# FSS_FSAS_OTFA_REGS_53802000h register map
Vendor: Texas Instruments
Peripheral module from a debugger description file (folder AM261x).
Registers are 32-bit, read-write, reset 0x0 unless marked. A register's access mark holds for its fields unless they carry their own. Offsets are as the file gives them; lines under a group give offsets from that group; [hi:lo] are bit positions; {n}, {i} and the like mark numbered series; 'fields as' and 'values as' point back to an identical list; <NAME> marks a mode.

## FSAS_OTFA_REGS
0x00 FSAS_OTFA_REGS_REVID ro reset 0x47500101 — This register defines the revision and functional ID.
0x04 FSAS_OTFA_REGS_SCFG reset 0x2 — This register defines the power IDLE mode.
  [1:0] IDLE_MODE — IDLE MODE. 0x0: Force-idle mode: local target's idle state follows (acknowledges) the system's idle requests unconditionally, i.e. regardless of the IP module's internal requirements. Backup mode, for debug only. 0x1: No-idle mode: local target never enters idle state. Backup mode, for debug only. 0x2: Smart-idle mode: local target's idle state eventually follows (acknowledges) the system's idle requests, depending on the IP module's internal requirements. IP module shall not generate (IRQ- or DMA-request-related) wakeup events. 0x3: Reserved
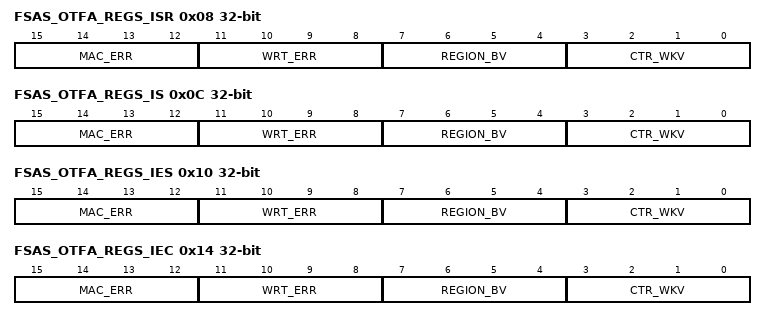
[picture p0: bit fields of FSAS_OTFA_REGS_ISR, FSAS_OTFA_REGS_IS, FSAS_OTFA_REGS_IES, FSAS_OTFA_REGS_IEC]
0x08 FSAS_OTFA_REGS_ISR — Per-event raw interrupt status vector Raw status is set even if event is not enabled. Write 1 to set the (raw) status, mostly for debug and SW testing.
  [15:12] MAC_ERR — Region MAC compare error event, Read MAC did not match the Write MAC. Write0:No action Read0:No event pending Read1:Event pending Write1:Set event (debug)
  [11:8] WRT_ERR — Region write error event, write cmd issues when write is disabled Write0:No action Read0:No event pending Read1:Event pending Write1:Set event (debug)
  [7:4] REGION_BV — Region overflow boundary event caused by a burst transaction crossed a start or end of a region. Write0:No action Read0:No event pending Read1:Event pending Write1:Set event (debug)
  [3:0] CTR_WKV — AES CTR enabled region violated Wrt Once Per Wrt Key rule. Write0:No action Read0:No event pending Read1:Event pending Write1:Set event (debug)
0x0C FSAS_OTFA_REGS_IS — Per-event 'enabled' interrupt status vector. Enabled status isn't set unless event is enabled. Write 1 to clear the status after interrupt has been serviced (raw status gets cleared, i.e. even if not enabled).
  [15:12] MAC_ERR — Region MAC compare error event, Read MAC did not match the Write MAC. Write0:No action Read0:No (enabled) event pending Read1:Event pending Write1:Clear event
  [11:8] WRT_ERR — Region write error event, write cmd issues when write is disabled. Write0:No action Read0:No (enabled) event pending Read1:Event pending Write1:Clear event
  [7:4] REGION_BV — Region overflow boundary event caused by a burst transaction crossing a start or end of a region. Write0:No action Read0:No (enabled) event pending Read1:Event pending Write1:Clear event Note: a RMW transaction can make create 2 events , 1st do to the orginal over lap and then 2nd do to the new wrt cmd. Also, a RM and RMW can create event on the 2nd transaction do to the over lap do to the expansion of the transaction.
  [3:0] CTR_WKV — AES CTR enabled region violated Wrt Once Per Wrt Key rule. Write0:No action Read0:No (enabled) event pending Read1:Event pending Write1:Clear event and reset counter
0x10 FSAS_OTFA_REGS_IES — Per-event interrupt enable bit vector. Write 1 to set (enable interrupt). Readout equal to corresponding _CLR register.
  [15:12] MAC_ERR — Region MAC compare error event, Read MAC did not match the Write MAC. Write0:No action Read0:Interrupt disabled (masked) Read1:Interrupt enabled Write1:Enable interrupt
  [11:8] WRT_ERR — Region write error event, write cmd issues when write is disabled. Write0:No action Read0:Interrupt disabled (masked) Read1:Interrupt enabled Write1:Enable interrupt
  [7:4] REGION_BV — Region overflow boundary event caused by a burst transaction crossing a start or end of a region. Write0:No action Read0:Interrupt disabled (masked) Read1:Interrupt enabled Write1:Enable interrupt
  [3:0] CTR_WKV — AES CTR enabled region violated Wrt Once Per Wrt Key rule. Write0:No action Read0:Interrupt disabled (masked) Read1:Interrupt enabled Write1:Enable interrupt
0x14 FSAS_OTFA_REGS_IEC — Per-event interrupt enable bit vector. Write 1 to clear (disable interrupt). Readout equal to corresponding _SET register.
  [15:12] MAC_ERR — Region MAC compare error event, Read MAC did not match the Write MAC. Write0:No action Read0:Interrupt disabled (masked) Read1:Interrupt enabled Write1:Enable interrupt
  [11:8] WRT_ERR — Region write error event, write cmd issues when write is disabled Write0:No action Read0:Interrupt disabled (masked) Read1:Interrupt enabled Write1:Disable interrupt
  [7:4] REGION_BV — Region overflow boundary event caused by a burst transaction crossing a start or end of a region. Write0:No action Read0:Interrupt disabled (masked) Read1:Interrupt enabled Write1:Disable interrupt
  [3:0] CTR_WKV — AES CTR enabled region violated Wrt Once Per Wrt Key rule. Write0:No action Read0:Interrupt disabled (masked) Read1:Interrupt enabled Write1:Disable interrupt
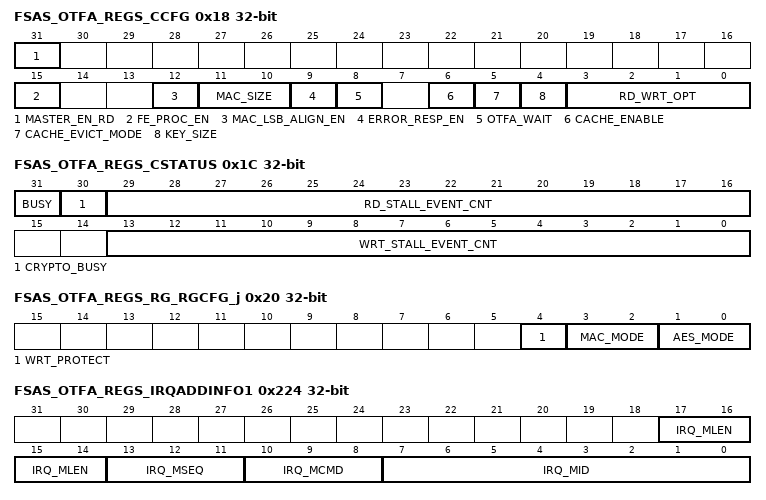
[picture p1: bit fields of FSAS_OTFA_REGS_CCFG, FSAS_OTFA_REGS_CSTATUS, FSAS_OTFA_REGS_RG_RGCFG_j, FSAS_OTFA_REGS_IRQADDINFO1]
0x18 FSAS_OTFA_REGS_CCFG — This register controls the enabling and the functionality of this AES core.
  [31] MASTER_EN_RD — This register controls the enabling and the functionality of this IP. Write0:Request to Disabled and enter into Bypass mode. Read0:Disabled and enter into Bypass mode is active When Disabled, then Bypass mux is enabled which will directly connect the otfa_emif4d ocp hp target port to the ocp hp master port. The OTFA core clock is gated in this mode. Write1:Request to Enabled mode Read1:Enabled mode is active When Enabled, all functionality is enabled and bypass mux will be disabled. Note: The SW most follow the defined programming procedure from switching states. Disable -> Enable and Enable -> Disable. See programming model for more details on the procedures that the SW needs to follow. The hw_disable_ctrl input port driven by Efuse bit will disable the ability for SW to set MasterEnable. hw_disable_ctrl = 1, then MasterEnable will be forced to 0, SW WRT will have no effect, SW will always read back 0. hw_disable_ctrl = 0, then MasterEnable state can get controlled by SW. Note: Optimization MMR should not be changed when MasterEnable is 0, after the first Disable -> Enable phase
  [15] FE_PROC_EN — This register allows the AES-CTR , GCM , GHASH modes to start the required AES jobs as soon as the RD CMD is passed through OTFA to help hide the AES op latency 0x0: Front End CMD AES start disable, only backend response , Legacy mode 0x1: Front End CMD AES start enabled, when enable only AES-CTR, GCM, and GHASH modes are supported
  [12] MAC_LSB_ALIGN_EN — This register controls shift of mac data to always LSB independent of address. 0x0: Default mode 0x1: Set, for FSS use case, updated Opti flash.
  [11:10] MAC_SIZE — This register defines the MAC size. 0x0: 4-bytes 0x1: 8-bytes 0x2: 12-bytes 0x3: 16-bytes.
  [9] ERROR_RESP_EN — This register controls the enable of of the OCP Error Response if a MAC error event occurred. The sys_SResp[1:0] will be drive to 3(Error Response) for data words which had the MAC error.
  [8] OTFA_WAIT — This register allows the ability to stop any new transactions from getting accepted and allow the current transactions to complete. Note: The otfa_emif has a one deep receive pipe stage, this will allow one new crypto cmd to get accepted before backpressure is asserted. Rules: Wait assertion can occur at any time. Wait de-assertion should only occur when CSTATUS.Busy is cleared SW needs to verify CSTATUS.Busy is cleared before it updates crypto region attributes. Non-Crypto transactions get accepted when Wait is asserted.
  [6] CACHE_ENABLE — This register controls the enable of the MAC cache Rd buffer. 0x0: Disabled 0x1: Enabled
  [5] CACHE_EVICT_MODE
  [4] KEY_SIZE — This register controls the key size used for all AES operations. 0x0: 128 Bit 0x1: 256 Bit
  [3:0] RD_WRT_OPT — This register defines the static allocation of the AES/GHASH cores to read transactions and write transactions. Adjusted only allowed before the OTFA is enabled for first time or after Enable must use the wait/busy method. 0x0: Read and Write is balanced. 50% of the Cypto cores on the Read Pipe 50% of the Cypto cores on the Write Pipe 0x1: Read optimized 75% of the Cypto cores on the Read Pipe 25% of the Cypto cores on the Write Pipe 0x2: Write optimized 25% of the Cypto cores on the Read Pipe 75% of the Cypto cores on the Write Pipe 0xF-0x3: Reserved
0x1C FSAS_OTFA_REGS_CSTATUS access not given — This is the status register which can be used to fine tune the AES core allocation to the Rd Pipe and Wrt Pipe along with a global activity status. Performance Counters which counts the number of events which causes high latency.
  [31] BUSY ro — 0x0: No transactions are active, crypto or non-crypto. 0x1: One or more transactions are active, crypto or non-crypto SW needs to read 2 consecutive 0 with 100ns delay or more between samples to insure the pipe is fully empty
  [30] CRYPTO_BUSY ro — 0x0: No crypto transactions are active 0x1: One or more crypto transactions are active. SW needs to read 2 consecutive 0 with 100ns delay or more between samples to insure the pipe is fully empty
  [29:16] RD_STALL_EVENT_CNT — Read the number of Rd Pipe full events. The counter increments every clock.event that we have no more rd cores available for a new transaction. Saturates to 0x3FFF. Any Write to CSTATUS reset RdStallEventCnt and WrtStallEventCnt to 0x0. (access R/W1TC)
  [13:0] WRT_STALL_EVENT_CNT — Read the number of Wrt Pipe full events. The counter increments every clock.event that we have no more wrt cores available for a new transaction. Saturates to 0x3FFF. Any Write to CSTATUS reset RdStallEventCnt and WrtStallEventCnt to 0x0. (access R/W1TC)
0x20 FSAS_OTFA_REGS_RG_RGCFG_j — RegionCfg
  [4] WRT_PROTECT, [3:2] MAC_MODE, [1:0] AES_MODE
0x24 FSAS_OTFA_REGS_RG_RGMACST_j — RegionMacStart
  [19:0] M_START — This defines the start of the mac buffer in 4KBytes steps
0x28 FSAS_OTFA_REGS_RG_RGST_j — RegionStart
  [19:0] R_START — This defines the start of the crypto region in 4KBytes steps
0x2C FSAS_OTFA_REGS_RG_RGSI_j — RegionSize
  [19:0] R_SIZE — This defines the size of the crypto region in 4KBytes steps
0x30 FSAS_OTFA_REGS_RG_RKEYE_j_k — RegionKeyE
  [31:0] R_KEY_E — Key E
0x50 FSAS_OTFA_REGS_RG_RKEYEP_j_k — RegionKeyEP
  [31:0] R_KEY_EP — Key EP
0x70 FSAS_OTFA_REGS_RG_RKEYA_j_k — RegionKeyA
  [31:0] R_KEY_A — Key A
0x80 FSAS_OTFA_REGS_RG_RKEYAP_j_k — RegionKeyAP
  [31:0] R_KEY_AP — Key AP
0x90 FSAS_OTFA_REGS_RG_RIV_j_k — RegionIV
  [31:0] R_IV — IV
0x220 FSAS_OTFA_REGS_IRQADDINFO0 ro — IRQAdditionalInfo0 .
  [31:0] IRQ_MADDR — Master Address which caused the event. Note During MAC Error Events a new response can over write the data. Another method to debug is to enable error response , this can also be used to mark which transaction caused the error.
0x224 FSAS_OTFA_REGS_IRQADDINFO1 ro — IRQAdditionalInfo1 .
  [17:14] IRQ_MLEN — Master OCP LENGTH which caused the event
  [13:11] IRQ_MSEQ — Master OCP Seq which caused the event. Not avalible for MAC error events
  [10:8] IRQ_MCMD — Master OCP CMD which caused the event. Note: During MAC Error Events a new response can over write the data. Another method to debug is to enable error response , this can also be used to mark which transaction caused the error.
  [7:0] IRQ_MID — Master OCP ID which caused the event Note: During MAC Error Events a new response can over write the data. Another method to debug is to enable error response , this can also be used to mark which transaction caused the error.
0x228 FSAS_OTFA_REGS_MACCACHEINFO ro — MACCacheInfo .
  [15:0] CACHE_MISS_EVENT_CNT — Counts the number of Cache Miss events. Saturates to 0xFFFF Any Write to reset to 0x0 Note that any Read Transaction that crosses a cache line will trigger a cache miss and 2 lines will be read. Also, any Write Transaction that crosses a cache line will mark both lines dirty.
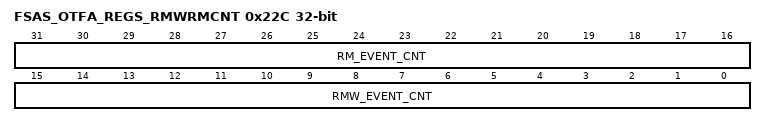
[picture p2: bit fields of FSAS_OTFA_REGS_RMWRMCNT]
0x22C FSAS_OTFA_REGS_RMWRMCNT ro — RMWRMCnt .
  [31:16] RM_EVENT_CNT — Counts the number of RM events. Saturates to 0xFFFF Any Write to RMWRMCNT will reset rm_event_cnt and rmw_event_cnt
  [15:0] RMW_EVENT_CNT — Counts the number of RMW events. Saturates to 0xFFFF Any Write to RMWRMCNT will reset rm_event_cnt and rmw_event_cnt
